# spixfm_reva_me55 register map
Registers are access not given, no defined reset value unless marked. A register's access mark holds for its fields unless they carry their own. Offsets are from the block's base; lines under a group give offsets from that group; [hi:lo] are bit positions; {n}, {i} and the like mark numbered series; 'fields as' and 'values as' point back to an identical list; <NAME> marks a mode.

## Memory map
0x40026000 SPIXFM size 0x1000 — SPIXF Master

## SPIXFM — SPIXF Master
Base 0x40026000
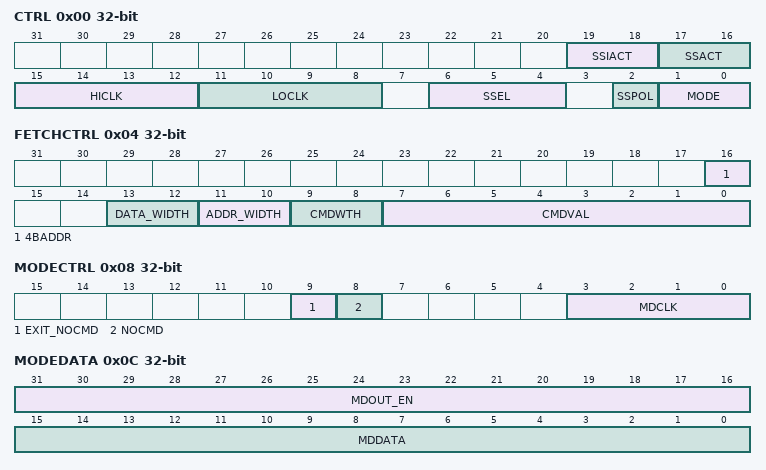
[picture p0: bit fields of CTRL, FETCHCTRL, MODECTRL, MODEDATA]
0x00 CTRL — SPIX Control Register.
  [19:18] SSIACT — Slave Select Inactive Timing.
    0=for_1_mod_clk (1 system clocks.); 1=for_3_mod_clk (3 System clocks.); 2=for_5_mod_clk (5 System clocks.); 3=for_9_mod_clk (9 System clocks.)
  [17:16] SSACT — Slave Select Active Timing.
    0=off (0 system clocks.); 1=for_2_mod_clk (2 System clocks.); 2=for_4_mod_clk (4 System clocks.); 3=for_8_mod_clk (8 System clocks.)
  [15:12] HICLK — Number of system clocks that SCLK will be high when SCLK pulses are generated.
  [11:8] LOCLK — Number of system clocks that SCLK will be low when SCLK pulses are generated.
  [6:4] SSEL — Slave Select. Only valid value is zero.
  [2] SSPOL — Slave Select Polarity.
    0=ACTIVE_HIGH (Slave Select is Active High.); 1=ACTIVE_LOW (Slave Select is Active Low.)
  [1:0] MODE — Defines SPI Mode, Only valid values are 0 and 3.
    0=SCLK_HI_SAMPLE_RISING; 3=SCLK_LO_SAMPLE_FAILLING
0x04 FETCHCTRL — SPIX Fetch Control Register.
  [16] 4BADDR — Four Byte Address Mode. Enables 4-byte Flash Address Mode.
    0=3 Byte Address Mode; 1=4 Byte Address Mode
  [13:12] DATA_WIDTH — Data Width. Number of data I/O used to receive data.
    0=Single SDIO; 1=Dual_IO (Dual SDIO.); 2=Quad_IO (Quad SDIO.); 3=Invalid
  [11:10] ADDR_WIDTH — Address Width. Number of data I/O used to send address, and mode/dummy clocks.
    values as DATA_WIDTH
  [9:8] CMDWTH — Command Width. Number of data I/O used to send commands.
    values as DATA_WIDTH
  [7:0] CMDVAL — Command Value sent to target to initiate fetching from SPI flash.
0x08 MODECTRL — SPIX Mode Control Register.
  [9] EXIT_NOCMD — Mode Send.
  [8] NOCMD — No Command Mode.
    0=always (Send read command every time SPI transaction is initiated.); 1=once (Send read command only once. NO read command in subsequent SPI transactions.)
  [3:0] MDCLK — Mode Clocks. Number of SPI clocks needed during mode/dummy phase of fetch.
0x0C MODEDATA — SPIX Mode Data Register.
  [31:16] MDOUT_EN — Mode Output Enable. Output enable state for each corresponding data bit in MD_DATA. 0: output enable off, I/O is tristate and 1: Output enable on, I/O is driving MD_DATA.
  [15:0] MDDATA — Mode Data. Specifies the data to send with the Dummy/Mode clocks.
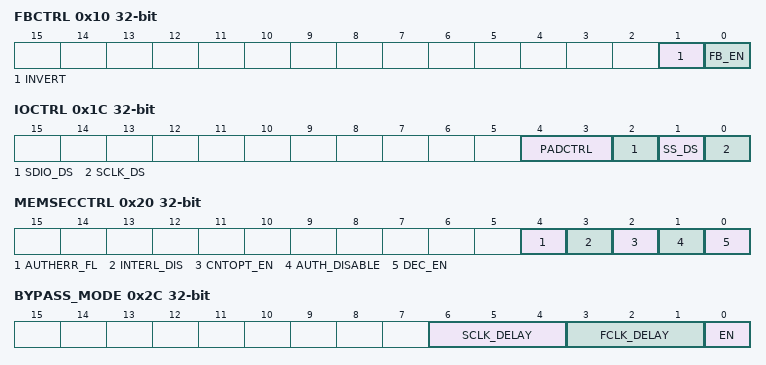
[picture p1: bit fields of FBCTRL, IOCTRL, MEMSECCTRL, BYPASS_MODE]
0x10 FBCTRL — SPIX Feedback Control Register.
  [1] INVERT — Invert SCLK in feedback mode.
    0=dis (Disable Invert SCLK feedback mode.); 1=en (Enable Invert SCLK feedback mode.)
  [0] FB_EN — Enable SCLK feedback mode.
    0=dis (Disable SCLK feedback mode.); 1=en (Enable SCLK feedback mode.)
0x1C IOCTRL — SPIX IO Control Register.
  [4:3] PADCTRL — IO Pullup/Pulldown Control. These bits control the pullups and pulldowns associated with all SPI XiP SDIO pins.
    0=tri_state; 1=Pull_Up; 2=Pull_down
  [2] SDIO_DS — SDIO Drive Strength. This bit controls the drive strength of all SDIO pins.
    0=Low (Low drive strength.); 1=High drive strength
  [1] SS_DS — Slave Select Drive Strength. This bit controls the drive strength on the dedicated slave select pin.
    0=Low (Low drive strength.); 1=High drive strength
  [0] SCLK_DS — SCLK drive Strength. This bit controls the drive strength on the SCLK pin.
    0=Low (Low drive strength.); 1=High drive strength
0x20 MEMSECCTRL — SPIX Memory Security Control Register.
  [4] AUTHERR_FL — Authentication Error Flag Bit.
  [3] INTERL_DIS — Disable authenticity interleaving (when authentication is enabled)
    1=dis (Disable interleaving of SPIX data.); 0=en (Enable interleaving of SPIX data.)
  [2] CNTOPT_EN — Enable counters optimization (when authentication is enabled).
    0=dis (Disable counter optimization.); 1=en (Enable counter optimization.)
  [1] AUTH_DISABLE — Integrity Enable.
    0=en (Integrity checking enabled.); 1=dis (Integrity checking disabled.)
  [0] DEC_EN — Decryption Enable.
    0=dis (Disable decryption of SPIX data.); 1=en (Enable decryption of SPIX data.)
0x24 BUSIDLE
  [15:0] BUSIDLE — A 16-bit timer will be triggered for each external access. The timer will be restarted if another access is performed before the timer expires. When the timer expires, slave select will be deactivated.
0x28 AUTHOFFSET
0x2C BYPASS_MODE
  [6:4] SCLK_DELAY
    0=0_NS; 1=0P5_NS (0.5ns); 2=1P0_NS (1.0ns); 3=1P5_NS (1.5ns); 4=2P0_NS (2.0ns); 5=2P5_NS (2.5ns); 6=3P0_NS (3.0ns); 7=3P5_NS (3.0ns)
  [3:1] FCLK_DELAY
    values as SCLK_DELAY
  [0] EN — Enable bypass.
